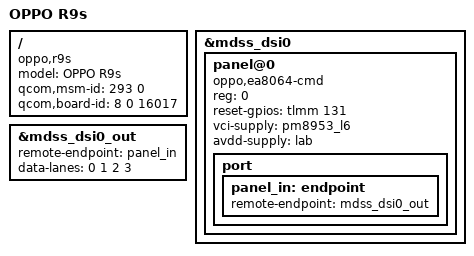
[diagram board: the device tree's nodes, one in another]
// SPDX-License-Identifier: BSD-3-Clause
/*
 * OPPO R9s (16017) —— MSM8953
 *
 * board-id <8 0 16017>：ABL 在启动时按这个三元组选 DTB。
 * 与 R9sk(16027) 的唯一区别就是 board-id 和机型名，
 * 硬件差异（面板 JDI/Samsung）在 mainline 的 simple-framebuffer
 * 方案下不体现 —— 屏幕内容由 bootloader 直接留在 framebuffer 里。
 */

/dts-v1/;

#include "msm8953-oppo-common.dtsi"

/ {
	model = "OPPO R9s";
	compatible = "oppo,r9s", "qcom,msm8953";

	qcom,msm-id = <293 0>;
	qcom,board-id = <8 0 16017>;
};

/*
 * 16017 的面板：Samsung EA8064 AMOLED
 *
 * reset 同 16027（都是 131，来自通用 oppo-msm8953/msm8953-mtp.dtsi 的
 * qcom,platform-reset-gpio）。AMOLED 的 AVDD/VNEG 来自 PMI8950 的
 * LAB/IBB 正负压轨：
 *   avdd-supply = <&lab>   正压
 *   vneg        = <&ibb>   负压（驱动里是 optional，先不接，避免无证据
 *                          直接上负压轨）
 *   vci         = 1.8V 逻辑供电（驱动里是必需项）
 */
&mdss_dsi0 {
	panel@0 {
		compatible = "oppo,ea8064-cmd";
		reg = <0>;

		reset-gpios = <&tlmm 131 GPIO_ACTIVE_HIGH>;

		vci-supply = <&pm8953_l6>;
		avdd-supply = <&lab>;

		port {
			panel_in: endpoint {
				remote-endpoint = <&mdss_dsi0_out>;
			};
		};
	};
};

/*
 * 面板 graph 必须**双向**连接。
 *
 * msm8953.dtsi 里 mdss_dsi0 的 port@1/endpoint 是空的（没有
 * remote-endpoint），而这里的 panel_in 指向它 —— 单向链接。
 *
 * 后果：devm_drm_of_get_bridge() → drm_of_find_panel_or_bridge()
 * → of_graph_get_remote_node(np, 1, 0) 读不到 remote-endpoint
 * 就返回 NULL，最终 -ENODEV；dsi_bind() 直接失败 →
 * component bind 失败 → **DSI 起不来、屏幕不亮**。
 *
 * dtc 其实会报 warning：
 *   Warning (graph_endpoint): graph connection to node
 *   '.../dsi@1a94000/ports/port@1/endpoint' is not bidirectional
 *
 * 上游所有用 panel 的板子都写了双向（对照 msm8916-samsung-a3u-eur.dts）。
 * R63452 / EA8064 都是 4 lane。
 */
&mdss_dsi0_out {
	remote-endpoint = <&panel_in>;
	data-lanes = <0 1 2 3>;
};
